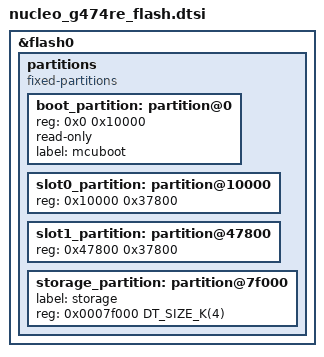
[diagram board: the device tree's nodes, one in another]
/* Flash layout definition shared by the application and the bootloader. */

&flash0 {
    partitions {
        compatible = "fixed-partitions";
        #address-cells = <1>;
        #size-cells = <1>;

        boot_partition: partition@0 {
            reg = <0x0 0x10000>;
            read-only;
            label = "mcuboot";
        };

        slot0_partition: partition@10000 {
            reg = <0x10000 0x37800>;
        };

        slot1_partition: partition@47800 {
            reg = <0x47800 0x37800>;
        };

        /* Set 4Kb of storage at the end of the 512Kb of flash */
        storage_partition: partition@7f000 {
            label = "storage";
            reg = <0x0007f000 DT_SIZE_K(4)>;
        };
    };
};
